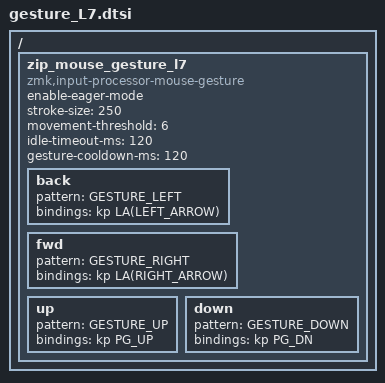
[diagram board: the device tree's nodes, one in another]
#include <dt-bindings/zmk/keys.h>

 / {
  zip_mouse_gesture_l7: zip_mouse_gesture_l7 {
    compatible = "zmk,input-processor-mouse-gesture";
    #input-processor-cells = <0>;

    enable-eager-mode;
    stroke-size = <250>;
    movement-threshold = <6>;
    idle-timeout-ms = <120>;
    gesture-cooldown-ms = <120>;

    /* 例: ブラウザ戻る/進む */
    back  { pattern = <GESTURE_LEFT>;  bindings = <&kp LA(LEFT_ARROW)>; };
    fwd   { pattern = <GESTURE_RIGHT>; bindings = <&kp LA(RIGHT_ARROW)>; };
    up    { pattern = <GESTURE_UP>;    bindings = <&kp PG_UP>; };
    down  { pattern = <GESTURE_DOWN>;  bindings = <&kp PG_DN>; };
  };
};
